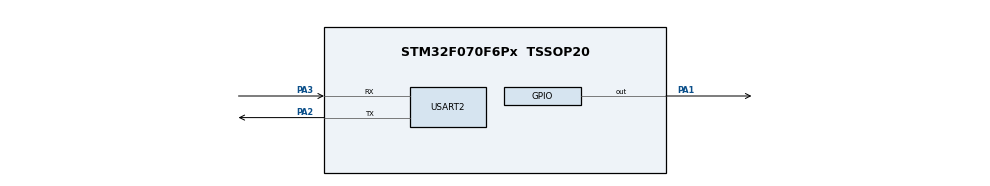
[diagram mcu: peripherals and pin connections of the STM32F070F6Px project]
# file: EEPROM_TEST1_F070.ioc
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Mcu.Family=STM32F0
Mcu.Name=STM32F070F6Px
Mcu.Package=TSSOP20
PA1.Signal=GPIO_Output
PA2.Mode=Asynchronous
PA2.Signal=USART2_TX
PA3.Mode=Asynchronous
PA3.Signal=USART2_RX
PF0-OSC_IN.Mode=HSE-External-Oscillator
PF0-OSC_IN.Signal=RCC_OSC_IN
PF1-OSC_OUT.Mode=HSE-External-Oscillator
PF1-OSC_OUT.Signal=RCC_OSC_OUT
ProjectManager.HeapSize=0x200
ProjectManager.StackSize=0x400
ProjectManager.TargetToolchain=STM32CubeIDE
USART2.VirtualMode-Asynchronous=VM_ASYNC
board=custom

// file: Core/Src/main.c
/* USER CODE BEGIN Header */
/**
  ******************************************************************************
  * @file           : main.c
  * @brief          : Main program body
  ******************************************************************************
  * @attention
  *
  * Copyright (c) 2023 STMicroelectronics.
  * All rights reserved.
  *
  * This software is licensed under terms that can be found in the LICENSE file
  * in the root directory of this software component.
  * If no LICENSE file comes with this software, it is provided AS-IS.
  *
  ******************************************************************************
  */
/* USER CODE END Header */
#include "main.h"

/* USER CODE BEGIN Includes */
#include "eeprom_emulated.h"
#include <stdio.h>
#include <string.h>

/* USER CODE END Includes */

/* USER CODE BEGIN PD */

//#define DATA1_ADDR (FLASH_BASE + 0x0800C000) // Example address for data1
//#define DATA2_ADDR (FLASH_BASE + 0x0800C004) // Example address for data2
#define DATA1_ADDR  0x08007000

/* USER CODE END PD */

UART_HandleTypeDef huart2;

void SystemClock_Config(void);
static void MX_GPIO_Init(void);
static void MX_USART2_UART_Init(void);

/* USER CODE BEGIN 0 */

uint8_t flag;

/* USER CODE END 0 */

int main(void)
{

  /* MCU Configuration--------------------------------------------------------*/

  /* Reset of all peripherals, Initializes the Flash interface and the Systick. */
  HAL_Init();

  /* Configure the system clock */
  SystemClock_Config();

  /* Initialize all configured peripherals */
  MX_GPIO_Init();
  MX_USART2_UART_Init();
  /* USER CODE BEGIN 2 */
  // Data to be written
  uint32_t data1 = 100;
 // uint32_t data2 = 50;

  // Print the data to be written using UART
  printf("Data to be written to EEPROM:\r\n");
  printf("Data1: %lu\r\n", data1);
  //printf("Data2: %lu\r\n", data2);

  // Write the first data to the emulated EEPROM
  Flash_Write_Data(DATA1_ADDR, &data1, sizeof(data1) / 4); // Divide by 4 to write in words
  printf("Data1 written to EEPROM.\r\n");

  // Write the second data to the emulated EEPROM
//  Flash_Write_Data(DATA2_ADDR, &data2, sizeof(data2) / 4); // Divide by 4 to write in words
//  printf("Data2 written to EEPROM.\r\n");

  HAL_Delay(1);

  // Read the first data from the emulated EEPROM
  uint32_t readData1;
  Flash_Read_Data(DATA1_ADDR, &readData1, sizeof(readData1) / 4);

//  // Read the second data from the emulated EEPROM
////  uint32_t readData2;
////  Flash_Read_Data(DATA2_ADDR, &readData2, sizeof(readData2) / 4);
//
//  // Print the read data using UART
  printf("Data read from EEPROM:\r\n");
  printf("Data1: %lu\r\n", readData1);
//  printf("Data2: %lu\r\n", readData2);

  /* USER CODE END 2 */

  /* Infinite loop */
  /* USER CODE BEGIN WHILE */
  while (1)
  {

	char buffer[100];
	sprintf(buffer, "Data read from EEPROM:\r\nData1: %lu\r\n", readData1);

	// Transmit the data over UART
	HAL_UART_Transmit(&huart2, (uint8_t*)buffer, strlen(buffer), HAL_MAX_DELAY);
    /* USER CODE END WHILE */

  }
}

void SystemClock_Config(void)
{
  RCC_OscInitTypeDef RCC_OscInitStruct = {0};
  RCC_ClkInitTypeDef RCC_ClkInitStruct = {0};

  /** Initializes the RCC Oscillators according to the specified parameters
  * in the RCC_OscInitTypeDef structure.
  */
  RCC_OscInitStruct.OscillatorType = RCC_OSCILLATORTYPE_HSI;
  RCC_OscInitStruct.HSIState = RCC_HSI_ON;
  RCC_OscInitStruct.HSICalibrationValue = RCC_HSICALIBRATION_DEFAULT;
  RCC_OscInitStruct.PLL.PLLState = RCC_PLL_NONE;
  if (HAL_RCC_OscConfig(&RCC_OscInitStruct) != HAL_OK)
  {
    Error_Handler();
  }

  /** Initializes the CPU, AHB and APB buses clocks
  */
  RCC_ClkInitStruct.ClockType = RCC_CLOCKTYPE_HCLK|RCC_CLOCKTYPE_SYSCLK
                              |RCC_CLOCKTYPE_PCLK1;
  RCC_ClkInitStruct.SYSCLKSource = RCC_SYSCLKSOURCE_HSI;
  RCC_ClkInitStruct.AHBCLKDivider = RCC_SYSCLK_DIV1;
  RCC_ClkInitStruct.APB1CLKDivider = RCC_HCLK_DIV1;

  if (HAL_RCC_ClockConfig(&RCC_ClkInitStruct, FLASH_LATENCY_0) != HAL_OK)
  {
    Error_Handler();
  }
}

static void MX_USART2_UART_Init(void)
{

  huart2.Instance = USART2;
  huart2.Init.BaudRate = 38400;
  huart2.Init.WordLength = UART_WORDLENGTH_8B;
  huart2.Init.StopBits = UART_STOPBITS_1;
  huart2.Init.Parity = UART_PARITY_NONE;
  huart2.Init.Mode = UART_MODE_TX_RX;
  huart2.Init.HwFlowCtl = UART_HWCONTROL_NONE;
  huart2.Init.OverSampling = UART_OVERSAMPLING_16;
  huart2.Init.OneBitSampling = UART_ONE_BIT_SAMPLE_DISABLE;
  huart2.AdvancedInit.AdvFeatureInit = UART_ADVFEATURE_NO_INIT;
  if (HAL_UART_Init(&huart2) != HAL_OK)
  {
    Error_Handler();
  }

}

static void MX_GPIO_Init(void)
{
  GPIO_InitTypeDef GPIO_InitStruct = {0};

  /* GPIO Ports Clock Enable */
  __HAL_RCC_GPIOF_CLK_ENABLE();
  __HAL_RCC_GPIOA_CLK_ENABLE();

  /*Configure GPIO pin Output Level */
  HAL_GPIO_WritePin(GPIOA, GPIO_PIN_1, GPIO_PIN_RESET);

  /*Configure GPIO pin : PA1 */
  GPIO_InitStruct.Pin = GPIO_PIN_1;
  GPIO_InitStruct.Mode = GPIO_MODE_OUTPUT_PP;
  GPIO_InitStruct.Pull = GPIO_NOPULL;
  GPIO_InitStruct.Speed = GPIO_SPEED_FREQ_LOW;
  HAL_GPIO_Init(GPIOA, &GPIO_InitStruct);

}

void Error_Handler(void)
{
  __disable_irq();
  while (1)
  {
  }
}
